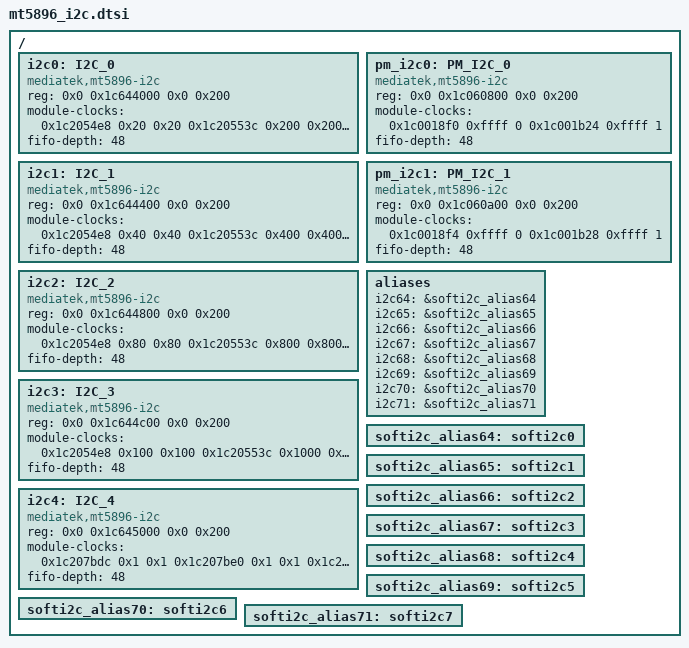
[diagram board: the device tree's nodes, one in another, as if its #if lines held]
// SPDX-License-Identifier: (GPL-2.0 OR BSD-3-Clause)
/*
 * Copyright (c) 2020 MediaTek Inc.
 */

/ {
	i2c0: I2C_0 {
		compatible = "mediatek,mt5896-i2c";
		reg = <0x0 0x1c644000 0x0 0x200>;
		/* interrupt-parent = <&mtk_intc2_irq_low>; */
		/* interrupts = <0x0 0xf 0x4>; */
		module-clocks = <0x1c2054e8 0x20 0x20
				 0x1c20553c 0x200 0x200
				 0x1c2071f0 0xffff 0
				 0x1c207b78 0x200 0x200
				 0x1c207bc4 0xffff 1>;
		fifo-depth = <48>;
		#address-cells = <1>;
		#size-cells = <0>;
	};

	i2c1: I2C_1 {
		compatible = "mediatek,mt5896-i2c";
		reg = <0x0 0x1c644400 0x0 0x200>;
		/* interrupt-parent = <&mtk_intc2_irq_low>; */
		/* interrupts = <0x0 0x10 0x4>; */
		module-clocks = <0x1c2054e8 0x40 0x40
				 0x1c20553c 0x400 0x400
				 0x1c2071f8 0xffff 0
				 0x1c207b78 0x400 0x400
				 0x1c207bc8 0xffff 1>;
		fifo-depth = <48>;
		#address-cells = <1>;
		#size-cells = <0>;
	};

	i2c2: I2C_2 {
		compatible = "mediatek,mt5896-i2c";
		reg = <0x0 0x1c644800 0x0 0x200>;
		/* interrupt-parent = <&mtk_intc2_irq_low>; */
		/* interrupts = <0x0 0x11 0x4>; */
		module-clocks = <0x1c2054e8 0x80 0x80
				 0x1c20553c 0x800 0x800
				 0x1c207200 0xffff 0
				 0x1c207b78 0x800 0x800
				 0x1c207bcc 0xffff 1>;
		fifo-depth = <48>;
		#address-cells = <1>;
		#size-cells = <0>;
	};

	i2c3: I2C_3 {
		compatible = "mediatek,mt5896-i2c";
		reg = <0x0 0x1c644c00 0x0 0x200>;
		/* interrupt-parent = <&mtk_intc2_irq_low>; */
		/* interrupts = <0x0 0x12 0x4>; */
		module-clocks = <0x1c2054e8 0x100 0x100
				 0x1c20553c 0x1000 0x1000
				 0x1c207208 0xffff 0
				 0x1c207b78 0x1000 0x1000
				 0x1c207bd0 0xffff 1>;
		fifo-depth = <48>;
		#address-cells = <1>;
		#size-cells = <0>;
	};

	i2c4: I2C_4 {
		compatible = "mediatek,mt5896-i2c";
		reg = <0x0 0x1c645000 0x0 0x200>;
		/* interrupt-parent = <&mtk_intc2_irq_low>; */
		/* interrupts = <0x0 0x12 0x4>; */
		module-clocks = <0x1c207bdc 0x1 0x1
				 0x1c207be0 0x1 0x1
				 0x1c207210 0xffff 0
				 0x1c207bc0 0x1 0x1
				 0x1c207bd4 0xffff 1>;
		fifo-depth = <48>;
		#address-cells = <1>;
		#size-cells = <0>;
	};

	pm_i2c0: PM_I2C_0 {
		compatible = "mediatek,mt5896-i2c";
		reg = <0x0 0x1c060800 0x0 0x200>;
		/* interrupt-parent = <&mtk_intc2_irq_low>; */
		/* interrupts = <0x0 0xf 0x4>; */
		module-clocks = <0x1c0018f0 0xffff 0
				 0x1c001b24 0xffff 1>;
		fifo-depth = <48>;
		#address-cells = <1>;
		#size-cells = <0>;
	};

	pm_i2c1: PM_I2C_1 {
		compatible = "mediatek,mt5896-i2c";
		reg = <0x0 0x1c060a00 0x0 0x200>;
		/* interrupt-parent = <&mtk_intc2_irq_low>; */
		/* interrupts = <0x0 0xf 0x4>; */
		module-clocks = <0x1c0018f4 0xffff 0
				 0x1c001b28 0xffff 1>;
		fifo-depth = <48>;
		#address-cells = <1>;
		#size-cells = <0>;
	};

	aliases {
#if IS_ENABLED(CONFIG_DM_SEQ_ALIAS)
		i2c64 = &softi2c_alias64;
		i2c65 = &softi2c_alias65;
		i2c66 = &softi2c_alias66;
		i2c67 = &softi2c_alias67;
		i2c68 = &softi2c_alias68;
		i2c69 = &softi2c_alias69;
		i2c70 = &softi2c_alias70;
		i2c71 = &softi2c_alias71;
#else
		/* make highest alias id to 63, so softi2c will start from 64 align kernel id */
		i2c63 = &pm_i2c1;
#endif
	};

	softi2c_alias64: softi2c0 {
		#address-cells = <1>;
		#size-cells = <0>;
	};

	softi2c_alias65: softi2c1 {
		#address-cells = <1>;
		#size-cells = <0>;
	};

	softi2c_alias66: softi2c2 {
		#address-cells = <1>;
		#size-cells = <0>;
	};

	softi2c_alias67: softi2c3 {
		#address-cells = <1>;
		#size-cells = <0>;
	};

	softi2c_alias68: softi2c4 {
		#address-cells = <1>;
		#size-cells = <0>;
	};

	softi2c_alias69: softi2c5 {
		#address-cells = <1>;
		#size-cells = <0>;
	};

	softi2c_alias70: softi2c6 {
		#address-cells = <1>;
		#size-cells = <0>;
	};

	softi2c_alias71: softi2c7 {
		#address-cells = <1>;
		#size-cells = <0>;
	};
};
